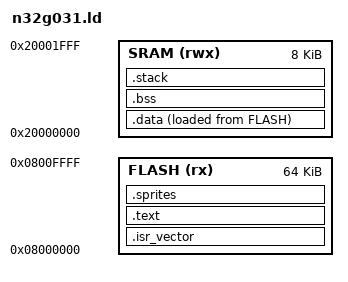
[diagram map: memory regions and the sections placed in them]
/* N32G031K8Q7-1 linker script
 * Flash: 64KB at 0x08000000
 * SRAM:  8KB  at 0x20000000
 */

MEMORY
{
    FLASH (rx)  : ORIGIN = 0x08000000, LENGTH = 64K
    SRAM  (rwx) : ORIGIN = 0x20000000, LENGTH = 8K
}

ENTRY(Reset_Handler)

_estack = ORIGIN(SRAM) + LENGTH(SRAM);

SECTIONS
{
    .isr_vector :
    {
        . = ALIGN(4);
        KEEP(*(.isr_vector))
        . = ALIGN(4);
    } > FLASH

    .text :
    {
        . = ALIGN(4);
        *(.text)
        *(.text*)
        *(.rodata)
        *(.rodata*)
        . = ALIGN(4);
        _etext = .;
    } > FLASH

    /* Sprite data in flash */
    .sprites :
    {
        . = ALIGN(4);
        _sprites_start = .;
        *(.sprites)
        *(.sprites*)
        . = ALIGN(4);
        _sprites_end = .;
    } > FLASH

    _sidata = LOADADDR(.data);

    .data :
    {
        . = ALIGN(4);
        _sdata = .;
        *(.data)
        *(.data*)
        . = ALIGN(4);
        _edata = .;
    } > SRAM AT > FLASH

    .bss :
    {
        . = ALIGN(4);
        _sbss = .;
        *(.bss)
        *(.bss*)
        *(COMMON)
        . = ALIGN(4);
        _ebss = .;
    } > SRAM

    .stack (NOLOAD) :
    {
        . = ALIGN(8);
        *(.stack)
    } > SRAM

    /DISCARD/ :
    {
        libc.a ( * )
        libm.a ( * )
        libgcc.a ( * )
    }
}
